# STM32N647xx register map
File version: 1.0
Registers are 32-bit, read-write, reset 0x0 unless marked. A register's access mark holds for its fields unless they carry their own. Offsets are from the block's base; [hi:lo] are bit positions; lines under a group give offsets from that group; {n}, {i} and the like mark numbered series.

## ADC12_COMMON
Base 0x40022300
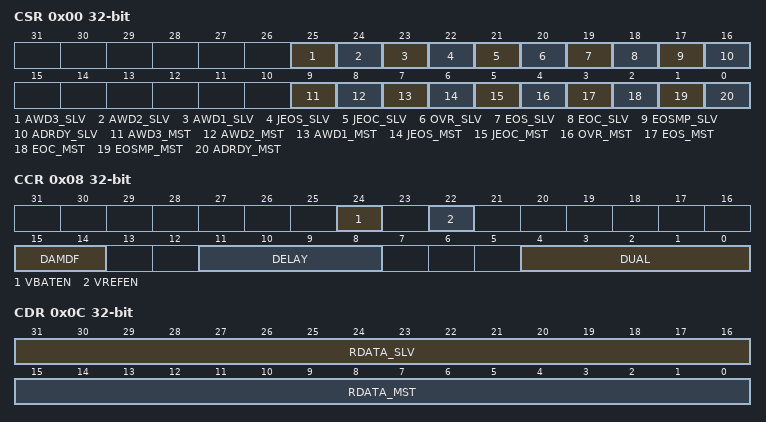
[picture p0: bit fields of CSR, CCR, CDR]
0x00 CSR — ADC common status register
  [25] AWD3_SLV — ADC multimode slave analog watchdog 3 flag
  [24] AWD2_SLV — ADC multimode slave analog watchdog 2 flag
  [23] AWD1_SLV — ADC multimode slave analog watchdog 1 flag
  [22] JEOS_SLV — ADC multimode slave group injected end of sequence conversions flag
  [21] JEOC_SLV — ADC multimode slave group injected end of unitary conversion flag
  [20] OVR_SLV — ADC multimode slave group regular overrun flag
  [19] EOS_SLV — ADC multimode slave group regular end of sequence conversions flag
  [18] EOC_SLV — ADC multimode slave group regular end of unitary conversion flag
  [17] EOSMP_SLV — ADC multimode slave group regular end of sampling flag
  [16] ADRDY_SLV — ADC multimode slave ready flag
  [9] AWD3_MST — ADC multimode master analog watchdog 3 flag
  [8] AWD2_MST — ADC multimode master analog watchdog 2 flag
  [7] AWD1_MST — ADC multimode master analog watchdog 1 flag
  [6] JEOS_MST — ADC multimode master group injected end of sequence conversions flag
  [5] JEOC_MST — ADC multimode master group injected end of unitary conversion flag
  [4] OVR_MST — ADC multimode master group regular overrun flag
  [3] EOS_MST — ADC multimode master group regular end of sequence conversions flag
  [2] EOC_MST — ADC multimode master group regular end of unitary conversion flag
  [1] EOSMP_MST — ADC multimode master group regular end of sampling flag
  [0] ADRDY_MST — ADC multimode master ready flag
0x08 CCR — ADC common control register
  [24] VBATEN — ADC internal path to battery voltage enable
  [22] VREFEN — ADC internal path to VrefInt enable
  [15:14] DAMDF — ADC multimode data format
  [11:8] DELAY — ADC multimode delay between 2 sampling phases
  [4:0] DUAL — ADC multimode mode selection
0x0C CDR — ADC common regular data register for dual mode
  [31:16] RDATA_SLV — ADC multimode slave group regular conversion data
  [15:0] RDATA_MST — ADC multimode master group regular conversion data
0x10 CDR2 — ADC common regular data register for dual mode 32-bit
  [31:0] RDATA_ALT — ADC multimode master or slave (alternated) group regular conversion data

## DBGMCU — Debug MCU
Base 0x44001000
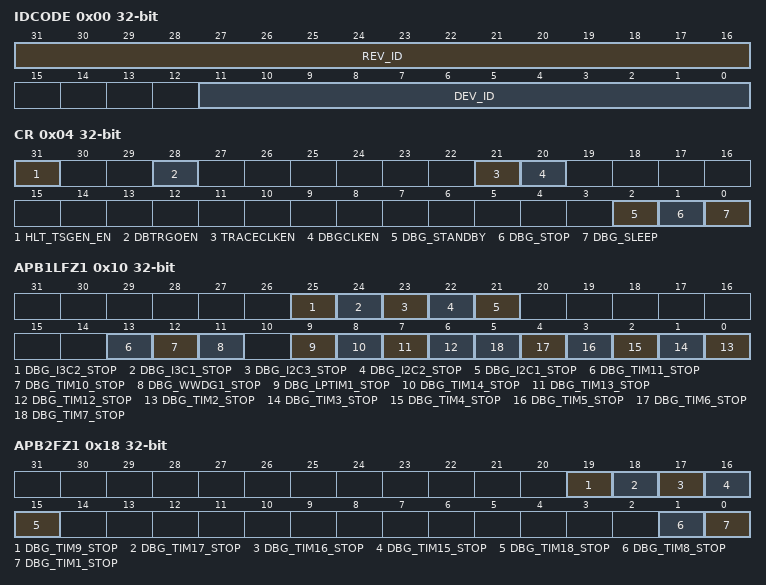
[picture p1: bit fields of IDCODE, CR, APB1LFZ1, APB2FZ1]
0x00 IDCODE — MCU device ID code
  [31:16] REV_ID — Revision ID
  [11:0] DEV_ID — Device ID
0x04 CR — Debug MCU configuration register
  [31] HLT_TSGEN_EN — TSGEN halt enable
  [28] DBTRGOEN — DBTRGIO connection control
    0=DBTRGIN (DBTRGIO connected to DBTRGIN); 1=DBTRGOUT (DBTRGIO connected to DBTRGOUT)
  [21] TRACECLKEN — TPIU export clock enable through software
  [20] DBGCLKEN — Debug clock enable through software
  [2] DBG_STANDBY — Allow debug in Standby mode
  [1] DBG_STOP — Allow debug in Stop mode
  [0] DBG_SLEEP — Allow debug in Sleep mode
0x10 APB1LFZ1 — Debug MCU APB1LFZ1 freeze register
  [25] DBG_I3C2_STOP — I3C2 SMBUS timeout stop in debug
  [24] DBG_I3C1_STOP — I3C1 SMBUS timeout stop in debug
  [23] DBG_I2C3_STOP — I2C3 SMBUS timeout stop in debug
  [22] DBG_I2C2_STOP — I2C2 SMBUS timeout stop in debug
  [21] DBG_I2C1_STOP — I2C1 SMBUS timeout stop in debug
  [13] DBG_TIM11_STOP — TIM11 stop in debug
  [12] DBG_TIM10_STOP — TIM10 stop in debug
  [11] DBG_WWDG1_STOP — WWDG1 stop in debug
  [9] DBG_LPTIM1_STOP — LPTIM1 stop in debug
  [8] DBG_TIM14_STOP — TIM14 stop in debug
  [7] DBG_TIM13_STOP — TIM13 stop in debug
  [6] DBG_TIM12_STOP — TIM12 stop in debug
  [n-2] DBG_TIM{n}_STOP (n=2..7) — TIM{n} stop in debug
0x14 APB1HFZ1 — Debug MCU APB1HFZ1 freeze register
  [8] DBG_FDCAN_STOP — FDCAN stop in debug
0x18 APB2FZ1 — Debug MCU APB2FZ1 freeze register
  [19] DBG_TIM9_STOP — TIM9 stop in debug
  [18] DBG_TIM17_STOP — TIM17 stop in debug
  [17] DBG_TIM16_STOP — TIM16 stop in debug
  [16] DBG_TIM15_STOP — TIM15 stop in debug
  [15] DBG_TIM18_STOP — TIM18 stop in debug
  [1] DBG_TIM8_STOP — TIM8 stop in debug
  [0] DBG_TIM1_STOP — TIM1 stop in debug
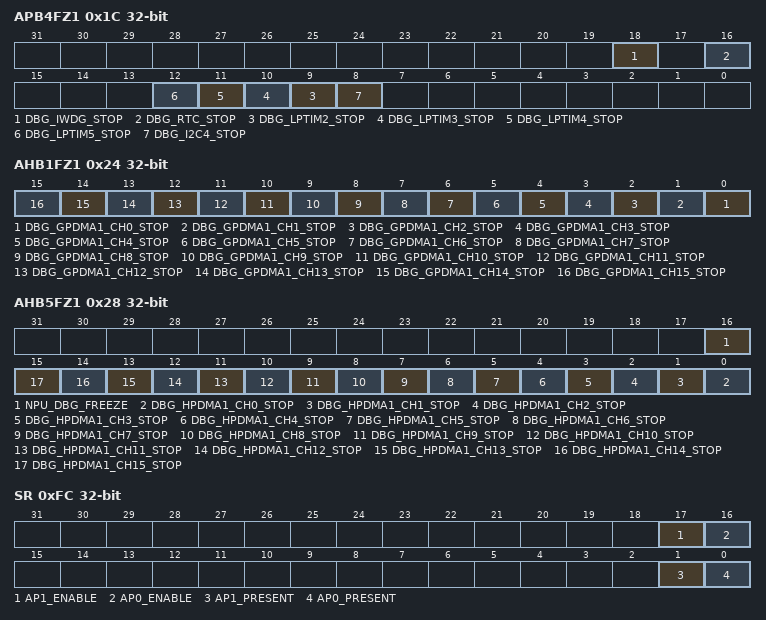
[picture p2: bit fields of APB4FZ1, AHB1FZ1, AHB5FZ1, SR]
0x1C APB4FZ1 — Debug MCU APB4FZ1 freeze register
  [18] DBG_IWDG_STOP — IWDG stop in debug
  [16] DBG_RTC_STOP — RTC stop in debug
  [n+7] DBG_LPTIM{n}_STOP (n=2..5) — LPTIM{n} stop in debug
  [8] DBG_I2C4_STOP — I2C4 stop in debug
0x20 APB5FZ1 — Debug MCU APB5FZ1 freeze register
  [4] DBG_GFXTIM_STOP — GFXTIM stop in debug
0x24 AHB1FZ1 — Debug MCU AHB1FZ1 freeze register
  [n] DBG_GPDMA1_CH{n}_STOP (n=0..15) — GPDMA1_CH{n} suspend in debug
0x28 AHB5FZ1 — Debug MCU AHB5FZ1 freeze register
  [16] NPU_DBG_FREEZE — NPU stop in debug mode
  [n] DBG_HPDMA1_CH{n}_STOP (n=0..15) — HPDMA1_CH{n} suspend in debug
0xFC SR — Debug MCU status register
  [17] AP1_ENABLE — Access point 1 enable
  [16] AP0_ENABLE — Access point 0 enable
  [1] AP1_PRESENT — Access point 1 presence
  [0] AP0_PRESENT — Access point 0 presence
0x100 DBG_AUTH_HOST — Debug MCU authentication host register
  [31:0] MESSAGE — Message[31:0]
0x104 DBG_AUTH_DEV — Debug MCU authentication device register
  [31:0] MESSAGE — Message[31:0]
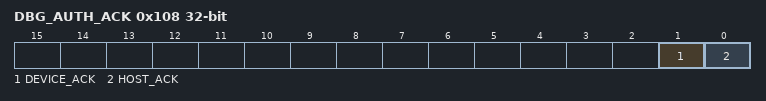
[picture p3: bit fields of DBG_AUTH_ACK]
0x108 DBG_AUTH_ACK — Debug MCU acknowledge authentication register
  [1] DEVICE_ACK — Access status to DBG_AUTH_DEV register
  [0] HOST_ACK — Access status to DBG_AUTH_HOST register
